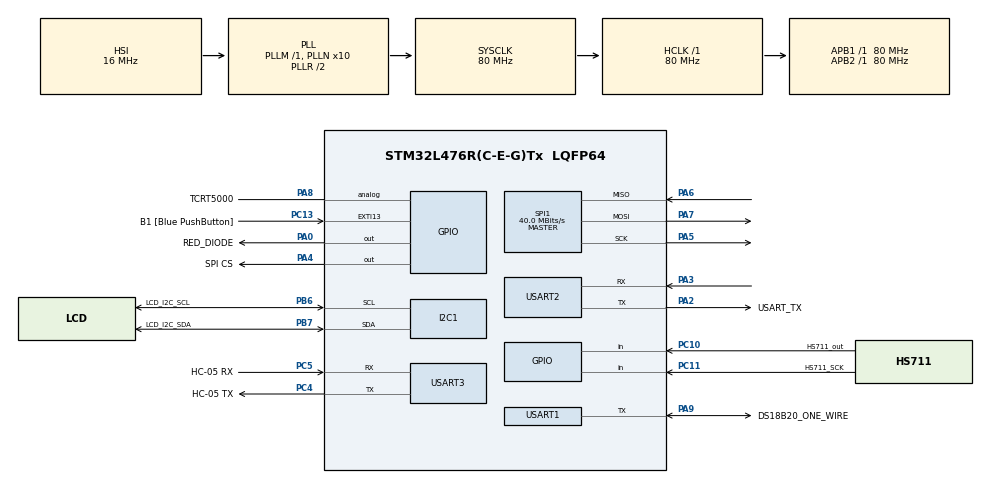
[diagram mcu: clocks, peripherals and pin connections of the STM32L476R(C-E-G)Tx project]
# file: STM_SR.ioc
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FATFS._MAX_SS=4096
FATFS._USE_LFN=1
I2C1.Timing=0x10909CEC
Mcu.Family=STM32L4
Mcu.Name=STM32L476R(C-E-G)Tx
Mcu.Package=LQFP64
NVIC.PriorityGroup=NVIC_PRIORITYGROUP_4
NVIC.USART1_IRQn=true\:0\:0\:false\:false\:true\:true\:true
NVIC.USART2_IRQn=true\:0\:0\:false\:false\:true\:true\:true
PA0.GPIO_Label=RED_DIODE
PA0.GPIO_ModeDefaultOutputPP=GPIO_MODE_OUTPUT_PP
PA0.GPIO_PuPd=GPIO_PULLDOWN
PA0.Signal=GPIO_Output
PA13\ (JTMS-SWDIO).GPIO_Label=TMS
PA13\ (JTMS-SWDIO).Mode=Serial_Wire
PA13\ (JTMS-SWDIO).Signal=SYS_JTMS-SWDIO
PA14\ (JTCK-SWCLK).GPIO_Label=TCK
PA14\ (JTCK-SWCLK).Mode=Serial_Wire
PA14\ (JTCK-SWCLK).Signal=SYS_JTCK-SWCLK
PA2.GPIO_Label=USART_TX
PA2.GPIO_Mode=GPIO_MODE_AF_PP
PA2.GPIO_PuPd=GPIO_NOPULL
PA2.GPIO_Speed=GPIO_SPEED_FREQ_VERY_HIGH
PA2.Mode=Asynchronous
PA2.Signal=USART2_TX
PA3.Mode=Asynchronous
PA3.Signal=USART2_RX
PA4.GPIO_Label=SPI CS
PA4.Signal=GPIO_Output
PA5.Mode=Full_Duplex_Master
PA5.Signal=SPI1_SCK
PA6.Mode=Full_Duplex_Master
PA6.Signal=SPI1_MISO
PA7.Mode=Full_Duplex_Master
PA7.Signal=SPI1_MOSI
PA8.GPIO_Label=TCRT5000
PA8.Signal=GPIO_Analog
PA9.GPIO_Label=DS18B20_ONE_WIRE
PA9.Mode=Half_duplex(single_wire_mode)
PA9.Signal=USART1_TX
PB3\ (JTDO-TRACESWO).GPIO_Label=SWO
PB3\ (JTDO-TRACESWO).Signal=SYS_JTDO-SWO
PB6.GPIO_Label=LCD_I2C_SCL
PB6.Mode=I2C
PB6.Signal=I2C1_SCL
PB7.GPIO_Label=LCD_I2C_SDA
PB7.Mode=I2C
PB7.Signal=I2C1_SDA
PC10.GPIO_Label=HS711_out
PC10.Signal=GPIO_Input
PC11.GPIO_Label=HS711_SCK
PC11.Signal=GPIO_Input
PC13.GPIO_Label=B1 [Blue PushButton]
PC13.GPIO_ModeDefaultEXTI=GPIO_MODE_IT_FALLING
PC13.GPIO_PuPd=GPIO_NOPULL
PC13.Signal=GPXTI13
PC14-OSC32_IN\ (PC14).Mode=LSE-External-Oscillator
PC14-OSC32_IN\ (PC14).Signal=RCC_OSC32_IN
PC15-OSC32_OUT\ (PC15).Mode=LSE-External-Oscillator
PC15-OSC32_OUT\ (PC15).Signal=RCC_OSC32_OUT
PC4.GPIO_Label=HC-05 TX
PC4.Mode=Asynchronous
PC4.Signal=USART3_TX
PC5.GPIO_Label=HC-05 RX
PC5.Mode=Asynchronous
PC5.Signal=USART3_RX
PH0-OSC_IN\ (PH0).Signal=RCC_OSC_IN
PH1-OSC_OUT\ (PH1).Signal=RCC_OSC_OUT
ProjectManager.HeapSize=0x200
ProjectManager.StackSize=0x400
ProjectManager.TargetToolchain=STM32CubeIDE
RCC.ADCFreq_Value=64000000
RCC.AHBFreq_Value=80000000
RCC.APB1Freq_Value=80000000
RCC.APB1TimFreq_Value=80000000
RCC.APB2Freq_Value=80000000
RCC.APB2TimFreq_Value=80000000
RCC.CortexFreq_Value=80000000
RCC.HCLKFreq_Value=80000000
RCC.HSE_VALUE=8000000
RCC.HSI_VALUE=16000000
RCC.MSI_VALUE=4000000
RCC.PLLN=10
RCC.PLLSourceVirtual=RCC_PLLSOURCE_HSI
RCC.PREFETCH_ENABLE=1
RCC.SYSCLKFreq_VALUE=80000000
RCC.SYSCLKSource=RCC_SYSCLKSOURCE_PLLCLK
RCC.USBFreq_Value=64000000
RCC.VCOOutputFreq_Value=160000000
SPI1.CalculateBaudRate=40.0 MBits/s
SPI1.DataSize=SPI_DATASIZE_8BIT
SPI1.Direction=SPI_DIRECTION_2LINES
SPI1.Mode=SPI_MODE_MASTER
SPI1.VirtualType=VM_MASTER
USART1.VirtualMode-Half_duplex(single_wire_mode)=VM_ASYNC
USART2.VirtualMode-Asynchronous=VM_ASYNC
USART3.VirtualMode-Asynchronous=VM_ASYNC
VP_FATFS_VS_Generic.Mode=User_defined
VP_RTC_VS_RTC_Activate.Mode=RTC_Enabled
VP_TIM6_VS_ClockSourceINT.Mode=Enable_Timer
board=NUCLEO-L476RG

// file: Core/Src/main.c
/* USER CODE BEGIN Header */
/**
  ******************************************************************************
  * @file           : main.c
  * @brief          : Main program body
  ******************************************************************************
  * @attention
  *
  * <h2><center>&copy; Copyright (c) 2023 STMicroelectronics.
  * All rights reserved.</center></h2>
  *
  * This software component is licensed by ST under BSD 3-Clause license,
  * the "License"; You may not use this file except in compliance with the
  * License. You may obtain a copy of the License at:
  *                        opensource.org/licenses/BSD-3-Clause
  *
  ******************************************************************************
  */
/* USER CODE END Header */
#include "main.h"
#include "fatfs.h"
#include "i2c.h"
#include "rtc.h"
#include "spi.h"
#include "tim.h"
#include "usart.h"
#include "gpio.h"

void SystemClock_Config(void);

int main(void)
{

  /* MCU Configuration--------------------------------------------------------*/

  /* Reset of all peripherals, Initializes the Flash interface and the Systick. */
  HAL_Init();

  /* Configure the system clock */
  SystemClock_Config();

  /* Initialize all configured peripherals */
  MX_GPIO_Init();
  MX_USART2_UART_Init();
  MX_I2C1_Init();
  MX_SPI1_Init();
  MX_USART1_UART_Init();
  MX_USART3_UART_Init();
  MX_FATFS_Init();
  MX_RTC_Init();
  MX_TIM6_Init();

  /* Infinite loop */
  /* USER CODE BEGIN WHILE */
  while (1)
  {
	  HAL_GPIO_WritePin(RED_DIODE_GPIO_Port, RED_DIODE_Pin, GPIO_PIN_SET);
	  HAL_Delay(100);
	  HAL_GPIO_WritePin(RED_DIODE_GPIO_Port, RED_DIODE_Pin, GPIO_PIN_RESET);
	  HAL_Delay(100);
    /* USER CODE END WHILE */

  }
}

void SystemClock_Config(void)
{
  RCC_OscInitTypeDef RCC_OscInitStruct = {0};
  RCC_ClkInitTypeDef RCC_ClkInitStruct = {0};
  RCC_PeriphCLKInitTypeDef PeriphClkInit = {0};

  /** Initializes the RCC Oscillators according to the specified parameters
  * in the RCC_OscInitTypeDef structure.
  */
  RCC_OscInitStruct.OscillatorType = RCC_OSCILLATORTYPE_HSI|RCC_OSCILLATORTYPE_LSI;
  RCC_OscInitStruct.HSIState = RCC_HSI_ON;
  RCC_OscInitStruct.HSICalibrationValue = RCC_HSICALIBRATION_DEFAULT;
  RCC_OscInitStruct.LSIState = RCC_LSI_ON;
  RCC_OscInitStruct.PLL.PLLState = RCC_PLL_ON;
  RCC_OscInitStruct.PLL.PLLSource = RCC_PLLSOURCE_HSI;
  RCC_OscInitStruct.PLL.PLLM = 1;
  RCC_OscInitStruct.PLL.PLLN = 10;
  RCC_OscInitStruct.PLL.PLLP = RCC_PLLP_DIV7;
  RCC_OscInitStruct.PLL.PLLQ = RCC_PLLQ_DIV2;
  RCC_OscInitStruct.PLL.PLLR = RCC_PLLR_DIV2;
  if (HAL_RCC_OscConfig(&RCC_OscInitStruct) != HAL_OK)
  {
    Error_Handler();
  }
  /** Initializes the CPU, AHB and APB buses clocks
  */
  RCC_ClkInitStruct.ClockType = RCC_CLOCKTYPE_HCLK|RCC_CLOCKTYPE_SYSCLK
                              |RCC_CLOCKTYPE_PCLK1|RCC_CLOCKTYPE_PCLK2;
  RCC_ClkInitStruct.SYSCLKSource = RCC_SYSCLKSOURCE_PLLCLK;
  RCC_ClkInitStruct.AHBCLKDivider = RCC_SYSCLK_DIV1;
  RCC_ClkInitStruct.APB1CLKDivider = RCC_HCLK_DIV1;
  RCC_ClkInitStruct.APB2CLKDivider = RCC_HCLK_DIV1;

  if (HAL_RCC_ClockConfig(&RCC_ClkInitStruct, FLASH_LATENCY_4) != HAL_OK)
  {
    Error_Handler();
  }
  PeriphClkInit.PeriphClockSelection = RCC_PERIPHCLK_RTC|RCC_PERIPHCLK_USART1
                              |RCC_PERIPHCLK_USART2|RCC_PERIPHCLK_USART3
                              |RCC_PERIPHCLK_I2C1;
  PeriphClkInit.Usart1ClockSelection = RCC_USART1CLKSOURCE_PCLK2;
  PeriphClkInit.Usart2ClockSelection = RCC_USART2CLKSOURCE_PCLK1;
  PeriphClkInit.Usart3ClockSelection = RCC_USART3CLKSOURCE_PCLK1;
  PeriphClkInit.I2c1ClockSelection = RCC_I2C1CLKSOURCE_PCLK1;
  PeriphClkInit.RTCClockSelection = RCC_RTCCLKSOURCE_LSI;
  if (HAL_RCCEx_PeriphCLKConfig(&PeriphClkInit) != HAL_OK)
  {
    Error_Handler();
  }
  /** Configure the main internal regulator output voltage
  */
  if (HAL_PWREx_ControlVoltageScaling(PWR_REGULATOR_VOLTAGE_SCALE1) != HAL_OK)
  {
    Error_Handler();
  }
}

void Error_Handler(void)
{
}

/************************ (C) COPYRIGHT STMicroelectronics *****END OF FILE****/
